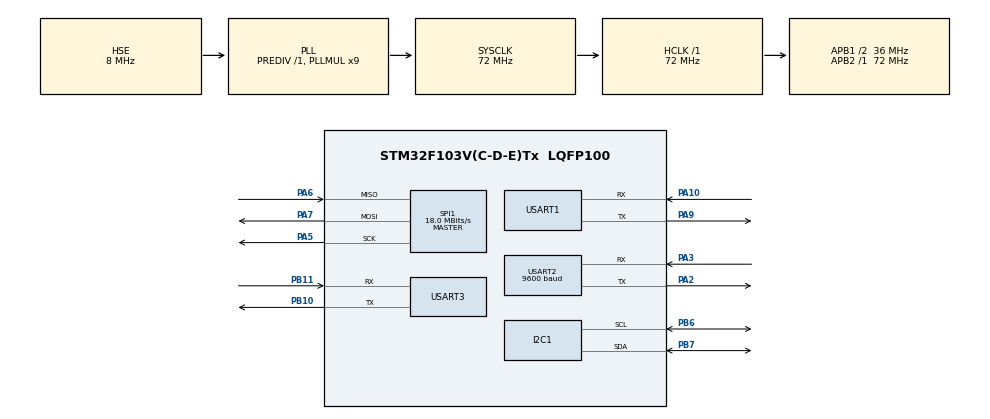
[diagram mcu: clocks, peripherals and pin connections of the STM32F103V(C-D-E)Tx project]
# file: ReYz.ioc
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Dma.MEMTOMEM.0.Direction=DMA_MEMORY_TO_MEMORY
Dma.MEMTOMEM.0.Instance=DMA2_Channel1
Dma.MEMTOMEM.0.MemDataAlignment=DMA_MDATAALIGN_BYTE
Dma.MEMTOMEM.0.MemInc=DMA_MINC_ENABLE
Dma.MEMTOMEM.0.Mode=DMA_NORMAL
Dma.MEMTOMEM.0.PeriphDataAlignment=DMA_PDATAALIGN_BYTE
Dma.MEMTOMEM.0.PeriphInc=DMA_PINC_ENABLE
Dma.MEMTOMEM.0.Priority=DMA_PRIORITY_LOW
Dma.Request0=MEMTOMEM
Mcu.Family=STM32F1
Mcu.Name=STM32F103V(C-D-E)Tx
Mcu.Package=LQFP100
NVIC.PriorityGroup=NVIC_PRIORITYGROUP_4
OSC_IN.Mode=HSE-External-Oscillator
OSC_IN.Signal=RCC_OSC_IN
OSC_OUT.Mode=HSE-External-Oscillator
OSC_OUT.Signal=RCC_OSC_OUT
PA10.Mode=Asynchronous
PA10.Signal=USART1_RX
PA13.Mode=JTAG_5_pins
PA13.Signal=SYS_JTMS-SWDIO
PA14.Mode=JTAG_5_pins
PA14.Signal=SYS_JTCK-SWCLK
PA15.Mode=JTAG_5_pins
PA15.Signal=SYS_JTDI
PA2.Mode=Asynchronous
PA2.Signal=USART2_TX
PA3.Mode=Asynchronous
PA3.Signal=USART2_RX
PA5.Mode=Full_Duplex_Master
PA5.Signal=SPI1_SCK
PA6.Mode=Full_Duplex_Master
PA6.Signal=SPI1_MISO
PA7.Mode=Full_Duplex_Master
PA7.Signal=SPI1_MOSI
PA9.Mode=Asynchronous
PA9.Signal=USART1_TX
PB10.Mode=Asynchronous
PB10.Signal=USART3_TX
PB11.Mode=Asynchronous
PB11.Signal=USART3_RX
PB3.Mode=JTAG_5_pins
PB3.Signal=SYS_JTDO-TRACESWO
PB4.Mode=JTAG_5_pins
PB4.Signal=SYS_NJTRST
PB6.Mode=I2C
PB6.Signal=I2C1_SCL
PB7.Mode=I2C
PB7.Signal=I2C1_SDA
ProjectManager.HeapSize=0x200
ProjectManager.StackSize=0x400
ProjectManager.TargetToolchain=SW4STM32
RCC.AHBFreq_Value=72000000
RCC.APB1CLKDivider=RCC_HCLK_DIV2
RCC.APB1Freq_Value=36000000
RCC.APB1TimFreq_Value=72000000
RCC.APB2Freq_Value=72000000
RCC.APB2TimFreq_Value=72000000
RCC.HCLKFreq_Value=72000000
RCC.PLLMUL=RCC_PLL_MUL9
RCC.PLLSourceVirtual=RCC_PLLSOURCE_HSE
RCC.SYSCLKFreq_VALUE=72000000
RCC.SYSCLKSource=RCC_SYSCLKSOURCE_PLLCLK
RCC.USBFreq_Value=72000000
SPI1.BaudRatePrescaler=SPI_BAUDRATEPRESCALER_4
SPI1.CLKPolarity=SPI_POLARITY_HIGH
SPI1.CalculateBaudRate=18.0 MBits/s
SPI1.Direction=SPI_DIRECTION_2LINES
SPI1.Mode=SPI_MODE_MASTER
SPI1.VirtualType=VM_MASTER
USART1.VirtualMode=VM_ASYNC
USART2.BaudRate=9600
USART2.VirtualMode=VM_ASYNC
USART3.VirtualMode=VM_ASYNC
board=custom

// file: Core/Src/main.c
/* USER CODE BEGIN Header */
/**
  ******************************************************************************
  * @file           : main.c
  * @brief          : Main program body
  ******************************************************************************
  * @attention
  *
  * Copyright (c) 2023 STMicroelectronics.
  * All rights reserved.
  *
  * This software is licensed under terms that can be found in the LICENSE file
  * in the root directory of this software component.
  * If no LICENSE file comes with this software, it is provided AS-IS.
  *
  ******************************************************************************
  */
/* USER CODE END Header */
#include "main.h"

/* USER CODE BEGIN Includes */
#include "yz_main.h"
//#include "yz_event_loop.h"
/* USER CODE END Includes */

 I2C_HandleTypeDef hi2c1;

SPI_HandleTypeDef hspi1;

UART_HandleTypeDef huart1;
UART_HandleTypeDef huart2;
UART_HandleTypeDef huart3;

DMA_HandleTypeDef hdma_memtomem_dma2_channel1;

void SystemClock_Config(void);
static void MX_GPIO_Init(void);
static void MX_I2C1_Init(void);
static void MX_SPI1_Init(void);
static void MX_DMA_Init(void);
static void MX_USART3_UART_Init(void);
static void MX_USART1_UART_Init(void);
static void MX_USART2_UART_Init(void);

int main(void)
{

  /* MCU Configuration--------------------------------------------------------*/

  /* Reset of all peripherals, Initializes the Flash interface and the Systick. */
  HAL_Init();

  /* Configure the system clock */
  SystemClock_Config();

  /* USER CODE BEGIN SysInit */
//  yz_init(&huart1,&huart2,&hi2c1,&hspi1);
  /* USER CODE END SysInit */

  /* Initialize all configured peripherals */
  MX_GPIO_Init();
  MX_I2C1_Init();
  MX_SPI1_Init();
  MX_DMA_Init();
  MX_USART3_UART_Init();
  MX_USART1_UART_Init();
  MX_USART2_UART_Init();
  /* USER CODE BEGIN 2 */
//  yz_main();
    yz_hal_set_i2c1(&hi2c1);
    yz_hal_set_spi1(&hspi1);
    yz_hal_set_uart1(&huart1);
    core_main();
  /* USER CODE END 2 */

  /* Infinite loop */
  /* USER CODE BEGIN WHILE */
  while (1)
  {
//      yz_loop_act();
    /* USER CODE END WHILE */

  }
}

void SystemClock_Config(void)
{
  RCC_OscInitTypeDef RCC_OscInitStruct = {0};
  RCC_ClkInitTypeDef RCC_ClkInitStruct = {0};

  /** Initializes the RCC Oscillators according to the specified parameters
  * in the RCC_OscInitTypeDef structure.
  */
  RCC_OscInitStruct.OscillatorType = RCC_OSCILLATORTYPE_HSE;
  RCC_OscInitStruct.HSEState = RCC_HSE_ON;
  RCC_OscInitStruct.HSEPredivValue = RCC_HSE_PREDIV_DIV1;
  RCC_OscInitStruct.HSIState = RCC_HSI_ON;
  RCC_OscInitStruct.PLL.PLLState = RCC_PLL_ON;
  RCC_OscInitStruct.PLL.PLLSource = RCC_PLLSOURCE_HSE;
  RCC_OscInitStruct.PLL.PLLMUL = RCC_PLL_MUL9;
  if (HAL_RCC_OscConfig(&RCC_OscInitStruct) != HAL_OK)
  {
    Error_Handler();
  }

  /** Initializes the CPU, AHB and APB buses clocks
  */
  RCC_ClkInitStruct.ClockType = RCC_CLOCKTYPE_HCLK|RCC_CLOCKTYPE_SYSCLK
                              |RCC_CLOCKTYPE_PCLK1|RCC_CLOCKTYPE_PCLK2;
  RCC_ClkInitStruct.SYSCLKSource = RCC_SYSCLKSOURCE_PLLCLK;
  RCC_ClkInitStruct.AHBCLKDivider = RCC_SYSCLK_DIV1;
  RCC_ClkInitStruct.APB1CLKDivider = RCC_HCLK_DIV2;
  RCC_ClkInitStruct.APB2CLKDivider = RCC_HCLK_DIV1;

  if (HAL_RCC_ClockConfig(&RCC_ClkInitStruct, FLASH_LATENCY_2) != HAL_OK)
  {
    Error_Handler();
  }
}

static void MX_I2C1_Init(void)
{

  hi2c1.Instance = I2C1;
  hi2c1.Init.ClockSpeed = 100000;
  hi2c1.Init.DutyCycle = I2C_DUTYCYCLE_2;
  hi2c1.Init.OwnAddress1 = 0;
  hi2c1.Init.AddressingMode = I2C_ADDRESSINGMODE_7BIT;
  hi2c1.Init.DualAddressMode = I2C_DUALADDRESS_DISABLE;
  hi2c1.Init.OwnAddress2 = 0;
  hi2c1.Init.GeneralCallMode = I2C_GENERALCALL_DISABLE;
  hi2c1.Init.NoStretchMode = I2C_NOSTRETCH_DISABLE;
  if (HAL_I2C_Init(&hi2c1) != HAL_OK)
  {
    Error_Handler();
  }

}

static void MX_SPI1_Init(void)
{

  /* SPI1 parameter configuration*/
  hspi1.Instance = SPI1;
  hspi1.Init.Mode = SPI_MODE_MASTER;
  hspi1.Init.Direction = SPI_DIRECTION_2LINES;
  hspi1.Init.DataSize = SPI_DATASIZE_8BIT;
  hspi1.Init.CLKPolarity = SPI_POLARITY_HIGH;
  hspi1.Init.CLKPhase = SPI_PHASE_1EDGE;
  hspi1.Init.NSS = SPI_NSS_SOFT;
  hspi1.Init.BaudRatePrescaler = SPI_BAUDRATEPRESCALER_4;
  hspi1.Init.FirstBit = SPI_FIRSTBIT_MSB;
  hspi1.Init.TIMode = SPI_TIMODE_DISABLE;
  hspi1.Init.CRCCalculation = SPI_CRCCALCULATION_DISABLE;
  hspi1.Init.CRCPolynomial = 10;
  if (HAL_SPI_Init(&hspi1) != HAL_OK)
  {
    Error_Handler();
  }

}

static void MX_USART1_UART_Init(void)
{

  huart1.Instance = USART1;
  huart1.Init.BaudRate = 115200;
  huart1.Init.WordLength = UART_WORDLENGTH_8B;
  huart1.Init.StopBits = UART_STOPBITS_1;
  huart1.Init.Parity = UART_PARITY_NONE;
  huart1.Init.Mode = UART_MODE_TX_RX;
  huart1.Init.HwFlowCtl = UART_HWCONTROL_NONE;
  huart1.Init.OverSampling = UART_OVERSAMPLING_16;
  if (HAL_UART_Init(&huart1) != HAL_OK)
  {
    Error_Handler();
  }

}

static void MX_USART2_UART_Init(void)
{

  huart2.Instance = USART2;
  huart2.Init.BaudRate = 9600;
  huart2.Init.WordLength = UART_WORDLENGTH_8B;
  huart2.Init.StopBits = UART_STOPBITS_1;
  huart2.Init.Parity = UART_PARITY_NONE;
  huart2.Init.Mode = UART_MODE_TX_RX;
  huart2.Init.HwFlowCtl = UART_HWCONTROL_NONE;
  huart2.Init.OverSampling = UART_OVERSAMPLING_16;
  if (HAL_UART_Init(&huart2) != HAL_OK)
  {
    Error_Handler();
  }

}

static void MX_USART3_UART_Init(void)
{

  huart3.Instance = USART3;
  huart3.Init.BaudRate = 115200;
  huart3.Init.WordLength = UART_WORDLENGTH_8B;
  huart3.Init.StopBits = UART_STOPBITS_1;
  huart3.Init.Parity = UART_PARITY_NONE;
  huart3.Init.Mode = UART_MODE_TX_RX;
  huart3.Init.HwFlowCtl = UART_HWCONTROL_NONE;
  huart3.Init.OverSampling = UART_OVERSAMPLING_16;
  if (HAL_UART_Init(&huart3) != HAL_OK)
  {
    Error_Handler();
  }

}

static void MX_DMA_Init(void)
{

  /* DMA controller clock enable */
  __HAL_RCC_DMA2_CLK_ENABLE();

  /* Configure DMA request hdma_memtomem_dma2_channel1 on DMA2_Channel1 */
  hdma_memtomem_dma2_channel1.Instance = DMA2_Channel1;
  hdma_memtomem_dma2_channel1.Init.Direction = DMA_MEMORY_TO_MEMORY;
  hdma_memtomem_dma2_channel1.Init.PeriphInc = DMA_PINC_ENABLE;
  hdma_memtomem_dma2_channel1.Init.MemInc = DMA_MINC_ENABLE;
  hdma_memtomem_dma2_channel1.Init.PeriphDataAlignment = DMA_PDATAALIGN_BYTE;
  hdma_memtomem_dma2_channel1.Init.MemDataAlignment = DMA_MDATAALIGN_BYTE;
  hdma_memtomem_dma2_channel1.Init.Mode = DMA_NORMAL;
  hdma_memtomem_dma2_channel1.Init.Priority = DMA_PRIORITY_LOW;
  if (HAL_DMA_Init(&hdma_memtomem_dma2_channel1) != HAL_OK)
  {
    Error_Handler( );
  }

}

static void MX_GPIO_Init(void)
{

  /* GPIO Ports Clock Enable */
  __HAL_RCC_GPIOA_CLK_ENABLE();
  __HAL_RCC_GPIOB_CLK_ENABLE();

}

void Error_Handler(void)
{
  __disable_irq();
  while (1)
  {
  }
}
